# STM32WL31 register map
File version: 1.2
CPU: CM0+ r0p0, little endian, MPU, no FPU, 4 interrupt priority bits
Registers are 32-bit, read-write, reset 0x0 unless marked. A register's access mark holds for its fields unless they carry their own. Offsets are from the block's base; lines under a group give offsets from that group; [hi:lo] are bit positions; {n}, {i} and the like mark numbered series; 'fields as' and 'values as' point back to an identical list; <NAME> marks a mode.

## Memory map
0x40000000 SYSTEM_CTRL size 0x48
0x40001000 FLASH_CTRL size 0x200 — 4kb addressable space
0x40002000 TIM2 size 0x6C — TIM2 address block description
0x40003000 IWDG size 0x14
0x40004000 RTC size 0x58
0x40005000 TIM16 size 0x6C — TIM16 address block description
0x40008000 DBGMCU size 0xC
0x41000000 I2C1 size 0x2C
0x41002000 SPI size 0x1C
0x41004000 USART size 0x30
0x41005000 LPUART size 0x30
0x41006000 ADC size 0x68 — ADC address block description
0x41007000 SPI3 size 0x24
0x48000000 GPIOA size 0x2C
0x48100000 GPIOB size 0x2C
0x48200000 CRC size 0x18
0x48400000 RCC size 0xB0
0x48500000 PWRC size 0xA8
0x48600000 RNG size 0x1000
0x48700000 DMA size 0xA4 — DMA address block description
0x48800000 DMAMUX size 0x20 — DMAMUX address block description
0x48900000 AES size 0x60
0x49000000 MR_SUBG size 0x400
0x49000400 STATIC size 0x40
0x49000500 DYNAMIC_REG size 0x40
0x49000600 STATUS size 0x40
0x49000700 MISC size 0x80
0x49000780 RETAINED size 0x80
0x49001040 SWITCHABLE size 0x40

## Interrupts
0 Flash (FLASH_CTRL) — Non-volatile memory (flash) controller
1 RCC — Reset and Clock Controller
2 PVD (PWRC) — PVD / BORH
3 I2C1 — I2C1 interrupt
5 SPI1 (SPI) — SPI1 interrupt
7 SPI3 — SPI3 interrupt
8 USART — USART interrupt
9 LPUART — LPUART interrupt
10 TIM2 — TIM2 interrupt
11 RTC — RTC interrupt
12 ADC — ADC interrupt
13 AES — AES interrupt
15 GPIOA — GPIOA interrupt
16 GPIOB — GPIOB interrupt
17 DMA — DMA interrupt
20 MR_SUBG_BUSY (MR_SUBG) — MR_SUBG Busy interrupt
21 MR_SUBG — MR_SUBG interrupt
22 TX_RX_SEQUENCE (MR_SUBG) — MR_SUBG TX/RX Sequence interrupt
26 TIM16 — TIM16 interrupt

## AES
Base 0x48900000
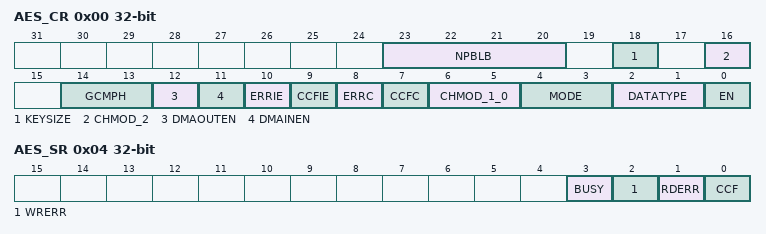
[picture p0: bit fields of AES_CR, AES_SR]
0x00 AES_CR
  [23:20] NPBLB — NPBLB: Number of Padding Bytes in Last Block of payload.
  [18] KEYSIZE — KEYSIZE: Key Size selection.
  [16] CHMOD_2 — CHMOD[2]: Chaining mode selection, bit [2]
  [14:13] GCMPH — GCMPH[1:0]: GCM or CCM Phase selection
  [12] DMAOUTEN — DMAOUTEN: DMA Output Enable
  [11] DMAINEN — DMAINEN: DMA Input Enable
  [10] ERRIE — ERRIE: Error Interrupt Enable
  [9] CCFIE — CCFIE: CCF Flag Interrupt Enable
  [8] ERRC — ERRC: Error clear
  [7] CCFC — CCFC: Computation Complete Flag Clear
  [6:5] CHMOD_1_0 — CHMOD[1:0]: AES Chaining Mode selection
  [4:3] MODE — MODE[1:0]: AES operating mode
  [2:1] DATATYPE — DATATYPE[1:0]: Data type selection
  [0] EN — EN: AES IP enable
0x04 AES_SR ro
  [3] BUSY — BUSY: Busy flag
  [2] WRERR — WRERR: Write error flag
  [1] RDERR — RDERR: Read error flag
  [0] CCF — CCF: Computation complete flag
0x08 AES_DINR
  [31:0] DINR — DINR[x+31:x]: One of four 32-bit words of a 128-bit input data block being written into the peripheral
0x0C AES_DOUTR ro
  [31:0] DOUTR — DOUTR[x+31:x]: One of four 32-bit words of a 128-bit output data block being read from the
{0x10+4i} AES_KEYR{i} (i=0..3) — AES_KEYRx register
  [31:0] KEY — KEY [((32*x)+31):((32*x)+0)]: Cryptographic key, bits [((32*x)+31):((32*x)+0)]
{0x20+4i} AES_IVR{i} (i=0..3) — AES_IVRx register
  [31:0] IVI — IVI [((32*x)+31):((32*x)+0)]: Initialization vector register (LSB IVR[((32*x)+31):((32*x)+0)])

## CRC
Base 0x48200000
0x00 CRC_DR reset 0xFFFFFFFF
  [31:0] DR — Data register bits. This register is used to write new data to the CRC calculator. It holds the previous CRC calculation result when it is read. If the data size is less than 32 bits, the least significant bits are used to write/read the correct value.
0x04 CRC_IDR
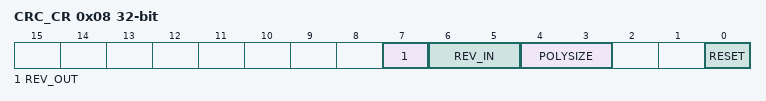
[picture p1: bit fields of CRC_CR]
0x08 CRC_CR
  [7] REV_OUT — Reverse output data This bit controls the reversal of the bit order of the output data. -0: Bit order not affected -1: Bit-reversed output format
  [6:5] REV_IN — Reverse input data These bits control the reversal of the bit order of the input data -00: Bit order not affected -01: Bit reversal done by byte -10: Bit reversal done by half-word -11: Bit reversal done by word
  [4:3] POLYSIZE — Polynomial size These bits control the size of the polynomial. -00: 32 bit polynomial -01: 16 bit polynomial -10: 8 bit polynomial -11: 7 bit polynomial
  [0] RESET — RESET bit This bit is set by software to reset the CRC calculation unit and set the data register to the value stored in the CRC_INIT register. This bit can only be set, it is automatically cleared by hardware
0x10 CRC_INIT reset 0xFFFFFFFF
  [31:0] INIT — Programmable initial CRC value This register is used to write the CRC initial value.
0x14 CRC_POL reset 0x4C11DB7
  [31:0] POL — POL[31:0]: Programmable polynomial This register is used to write the coefficients of the polynomial to be used for CRC calculation. If the polynomial size is less than 32 bits, the least significant bits have to be used to program the correct value.

## Notices in the file
Copyright (c) 2026 STMicroelectronics.
SPDX-License-Identifier: Apache-2.0
Licensed under the Apache License, Version 2.0 (the "License");
you may not use this file except in compliance with the License.
You may obtain a copy of the License at
http://www.apache.org/licenses/LICENSE-2.0
Unless required by applicable law or agreed to in writing, software
distributed under the License is distributed on an "AS IS" BASIS,
WITHOUT WARRANTIES OR CONDITIONS OF ANY KIND, either express or implied.
See the License for the specific language governing permissions and
limitations under the License.
